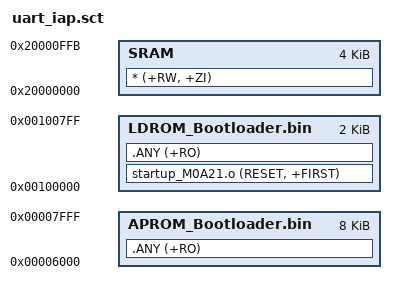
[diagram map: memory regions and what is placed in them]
LOAD_ROM_1  0x100000 0x800
{
	LDROM_Bootloader.bin  0x100000 0x800
	{
		startup_M0A21.o (RESET, +FIRST)
        .ANY (+RO)
	}
	
	SRAM  0x20000000 0xFFC
	{
		* (+RW, +ZI)
	}
}

LOAD_ROM_2  0x6000 0x2000
{
	APROM_Bootloader.bin  0x6000 0x2000
	{
        .ANY (+RO)
	}
}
